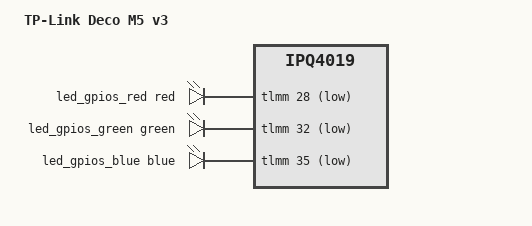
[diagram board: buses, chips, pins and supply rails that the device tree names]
// SPDX-License-Identifier: ISC
// Copyright (c) 2015, The Linux Foundation. All rights reserved.
// Copyright (c) 2021, Frank Veltmans <veltmans.frank@gmail.com>

#include "qcom-ipq4019-deco-m5.dtsi"

/ {
	model = "TP-Link Deco M5 v3";
	compatible = "tplink,deco-m5-v3";

	aliases {
		led-boot = &led_gpios_blue;
		led-failsafe = &led_gpios_red;
		led-running = &led_gpios_green;
		led-upgrade = &led_gpios_red;
	};

	led_gpios {
		status = "okay";
		compatible = "gpio-leds";

		led_gpios_red: led@0 {
			gpios = <&tlmm 28 GPIO_ACTIVE_LOW>;
			color = <LED_COLOR_ID_RED>;
			function = LED_FUNCTION_FAULT;
		};
		led_gpios_green: led@1 {
			gpios = <&tlmm 32 GPIO_ACTIVE_LOW>;
			color = <LED_COLOR_ID_GREEN>;
			function = LED_FUNCTION_POWER;
		};
		led_gpios_blue: led@2 {
			gpios = <&tlmm 35 GPIO_ACTIVE_LOW>;
			color = <LED_COLOR_ID_BLUE>;
			function = LED_FUNCTION_BOOT;
		};
	};
};
